# M4K2A register map
File version: 0.1
Registers are 32-bit, read-write, reset 0x0 unless marked. A register's access mark holds for its fields unless they carry their own. Offsets are from the block's base; [hi:lo] are bit positions; {n}, {i} and the like mark numbered series.

## SIWD
Base 0x400BB400
0x00 PRO reset 0x1E — SIWD Protect register
  [7:0] PROTECT
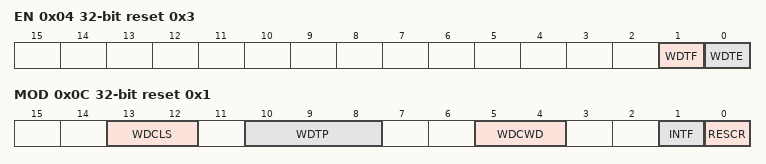
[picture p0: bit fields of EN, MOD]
0x04 EN reset 0x3 — SIWD Enable register
  [1] WDTF ro, [0] WDTE
0x08 CR wo (reset mask 0xFFFFFF00) — SIWD Control register
  [7:0] WDCR
0x0C MOD reset 0x1 — SIWD Mode register
  [13:12] WDCLS, [10:8] WDTP, [5:4] WDCWD, [1] INTF, [0] RESCR
0x10 MONI ro (reset mask 0xC0000000) — SIWD Monitor register
  [29:0] MONI
0x14 OSCCR — SIWD Oscillation control register
  [0] OSCPRO

## DNF
Base 0x400BB600
0x00 CKCR — DNF clock Control register
  [2:0] NFCKS
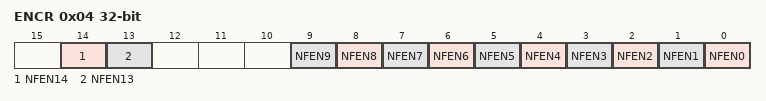
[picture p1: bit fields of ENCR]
0x04 ENCR — DNF Enable register
  [14] NFEN14, [13] NFEN13, [n] NFEN{n} (n=0..9)

## TSEL — TRGSEL
Base 0x400BB800
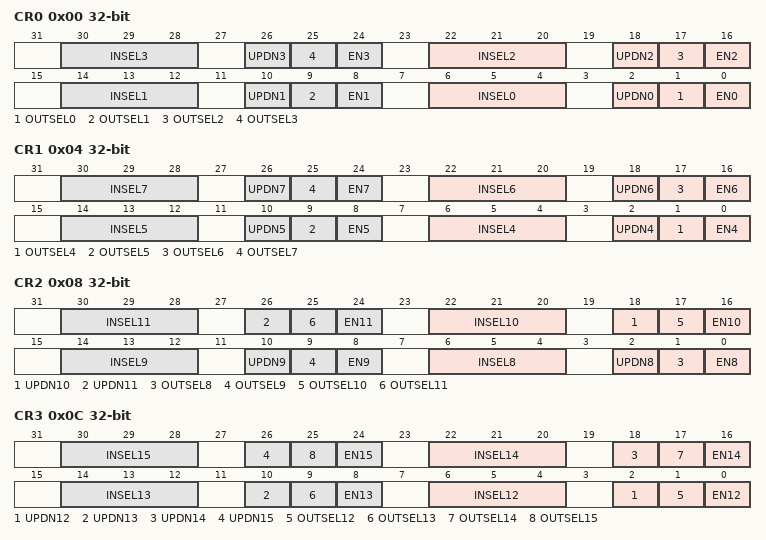
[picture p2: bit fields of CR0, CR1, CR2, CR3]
0x00 CR0 — TRGSEL Control register 0
  [8n+6:8n+4] INSEL{n} (n=0..3), [8n+2] UPDN{n} (n=0..3), [8n+1] OUTSEL{n} (n=0..3), [8n] EN{n} (n=0..3)
0x04 CR1 — TRGSEL Control register 1
  [8n-26:8n-28] INSEL{n} (n=4..7), [8n-30] UPDN{n} (n=4..7), [8n-31] OUTSEL{n} (n=4..7), [8n-32] EN{n} (n=4..7)
0x08 CR2 — TSEL Control register 2
  [8n-58:8n-60] INSEL{n} (n=8..11), [8n-62] UPDN{n} (n=8..11), [8n-63] OUTSEL{n} (n=8..11), [8n-64] EN{n} (n=8..11)
0x0C CR3 — TRGSEL Control register 3
  [8n-90:8n-92] INSEL{n} (n=12..15), [8n-94] UPDN{n} (n=12..15), [8n-95] OUTSEL{n} (n=12..15), [8n-96] EN{n} (n=12..15)
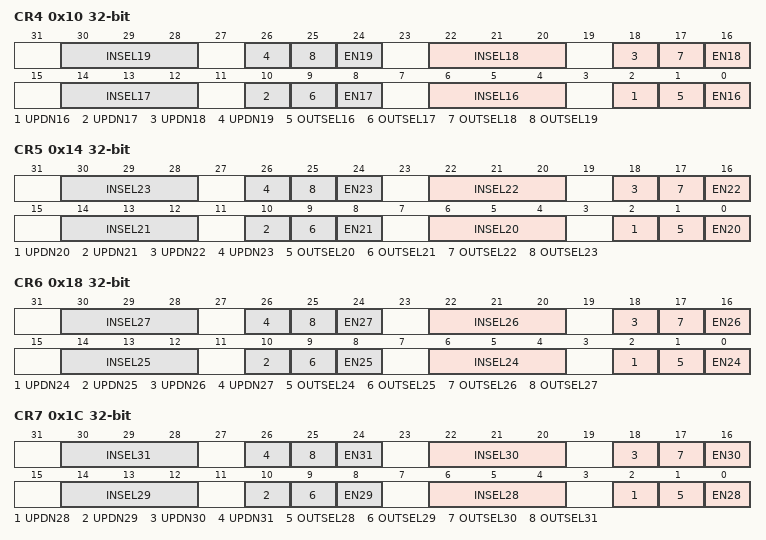
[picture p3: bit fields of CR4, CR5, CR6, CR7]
0x10 CR4 — TRGSEL Control register 4
  [8n-122:8n-124] INSEL{n} (n=16..19), [8n-126] UPDN{n} (n=16..19), [8n-127] OUTSEL{n} (n=16..19), [8n-128] EN{n} (n=16..19)
0x14 CR5 — TRGSEL Control register 5
  [8n-154:8n-156] INSEL{n} (n=20..23), [8n-158] UPDN{n} (n=20..23), [8n-159] OUTSEL{n} (n=20..23), [8n-160] EN{n} (n=20..23)
0x18 CR6 — TRGSEL Control register 6
  [8n-186:8n-188] INSEL{n} (n=24..27), [8n-190] UPDN{n} (n=24..27), [8n-191] OUTSEL{n} (n=24..27), [8n-192] EN{n} (n=24..27)
0x1C CR7 — TRGSEL Control register 7
  [8n-218:8n-220] INSEL{n} (n=28..31), [8n-222] UPDN{n} (n=28..31), [8n-223] OUTSEL{n} (n=28..31), [8n-224] EN{n} (n=28..31)
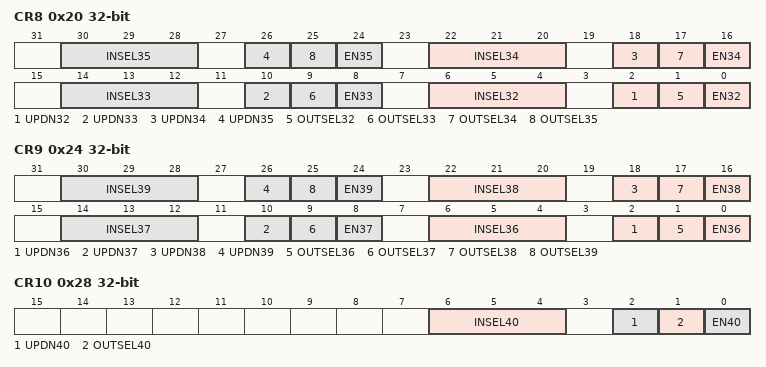
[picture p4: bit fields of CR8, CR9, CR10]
0x20 CR8 — TRGSEL Control register 8
  [8n-250:8n-252] INSEL{n} (n=32..35), [8n-254] UPDN{n} (n=32..35), [8n-255] OUTSEL{n} (n=32..35), [8n-256] EN{n} (n=32..35)
0x24 CR9 — TRGSEL Control register 9
  [8n-282:8n-284] INSEL{n} (n=36..39), [8n-286] UPDN{n} (n=36..39), [8n-287] OUTSEL{n} (n=36..39), [8n-288] EN{n} (n=36..39)
0x28 CR10 — TRGSEL Control register 10
  [6:4] INSEL40, [2] UPDN40, [1] OUTSEL40, [0] EN40

## RPAR — RAM Parity
Base 0x400BBB00
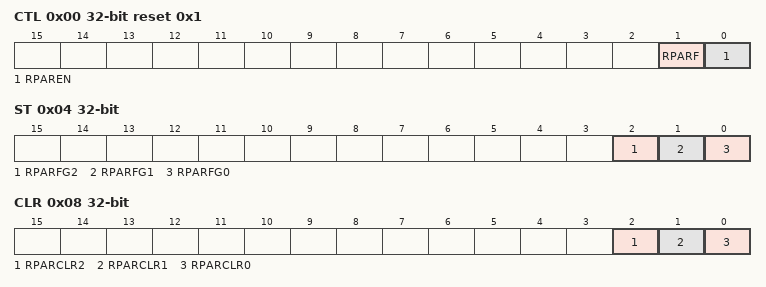
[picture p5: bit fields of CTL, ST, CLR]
0x00 CTL reset 0x1 — RAMM Parity control register
  [1] RPARF, [0] RPAREN
0x04 ST ro — RAMM Parity status register
  [2] RPARFG2, [1] RPARFG1, [0] RPARFG0
0x08 CLR wo — RAMM Parity status clear register
  [2] RPARCLR2, [1] RPARCLR1, [0] RPARCLR0
{0xC+4i} EAD{i} ro (i=0..2) — RAMM Parity Error address register {i}
  [31:0] RPAREADD{i}

## CRC
Base 0x400BBC00
0x00 DIN — CRC input data register
  [31:0] CRCDIN
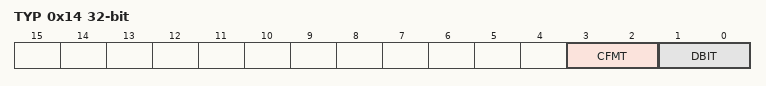
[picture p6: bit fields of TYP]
0x14 TYP — CRC data type register
  [3:2] CFMT, [1:0] DBIT
0x2C CLC reset 0xFFFFFFFF — CRC calculation result register
  [31:0] CRCCLC

## AMP
Base 0x400BC000
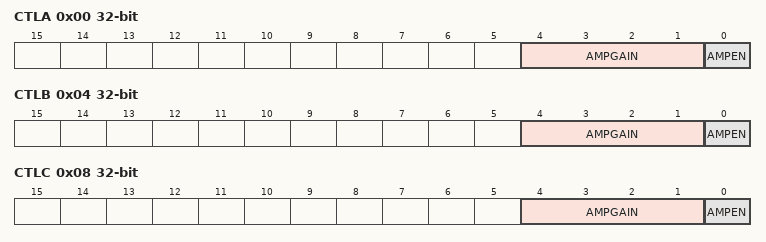
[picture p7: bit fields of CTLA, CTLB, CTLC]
0x00 CTLA — AMP control register A
  [4:1] AMPGAIN, [0] AMPEN
0x04 CTLB — AMP control register B
  [4:1] AMPGAIN, [0] AMPEN
0x08 CTLC — AMP control register C
  [4:1] AMPGAIN, [0] AMPEN

## PA — Port A
Base 0x400C0000
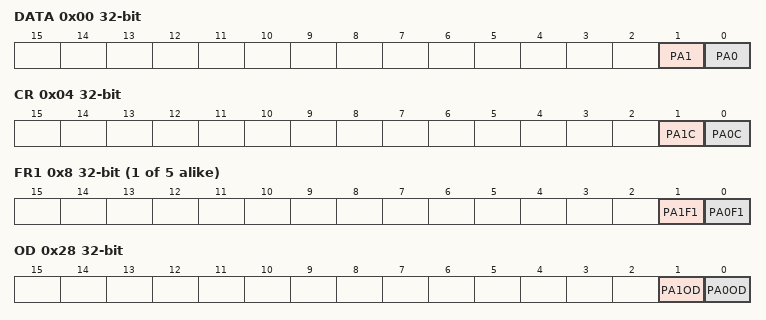
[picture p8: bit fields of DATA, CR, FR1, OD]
0x00 DATA — PA Data Register
  [1] PA1, [0] PA0
0x04 CR — PA Control Register
  [1] PA1C, [0] PA0C
{0x4+4i} FR{i} (i=1..5) — PA Function Register {i}
  [1] PA1F{i}, [0] PA0F{i}
0x28 OD — PA Open Drain Control Register
  [1] PA1OD, [0] PA0OD
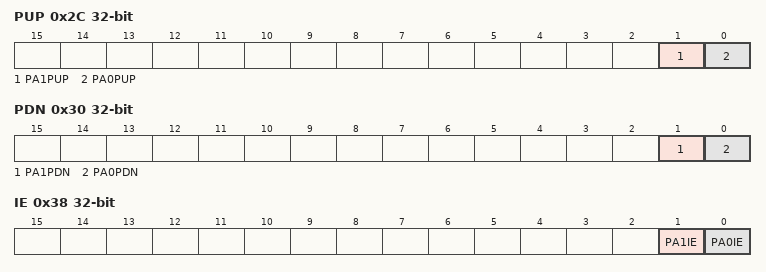
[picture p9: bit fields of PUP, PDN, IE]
0x2C PUP — PA Pull-up Control Register
  [1] PA1PUP, [0] PA0PUP
0x30 PDN — PA Pull-Down Control Register
  [1] PA1PDN, [0] PA0PDN
0x38 IE — PA Input Enable Control Register
  [1] PA1IE, [0] PA0IE

## PB — Port B
Base 0x400C0100
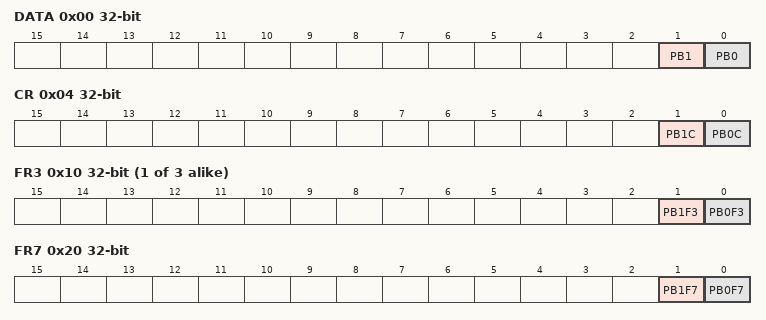
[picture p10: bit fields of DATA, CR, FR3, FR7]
0x00 DATA — PB Data Register
  [1] PB1, [0] PB0
0x04 CR — PB Control Register
  [1] PB1C, [0] PB0C
0x08 FR1 — PB Function Register 1
  [1] PB1F1
{0x4+4i} FR{i} (i=3..5) — PB Function Register {i}
  [1] PB1F{i}, [0] PB0F{i}
0x1C FR6 — PB Function Register 6
  [1] PB1F6
0x20 FR7 — PB Function Register 7
  [1] PB1F7, [0] PB0F7
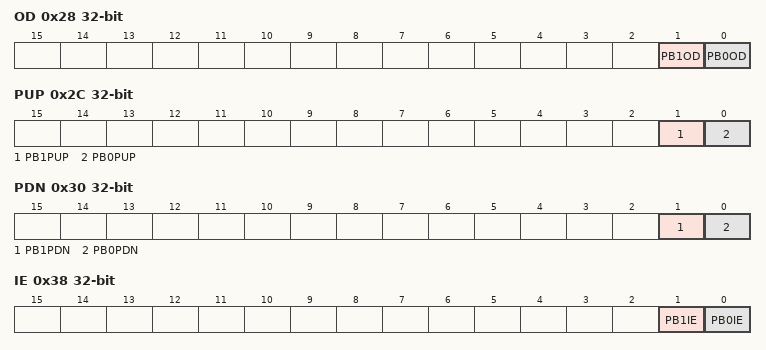
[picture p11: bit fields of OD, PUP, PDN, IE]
0x28 OD — PB Open Drain Control Register
  [1] PB1OD, [0] PB0OD
0x2C PUP — PB Pull-up Control Register
  [1] PB1PUP, [0] PB0PUP
0x30 PDN — PB Pull-Down Control Register
  [1] PB1PDN, [0] PB0PDN
0x38 IE — PB Input Enable Control Register
  [1] PB1IE, [0] PB0IE
